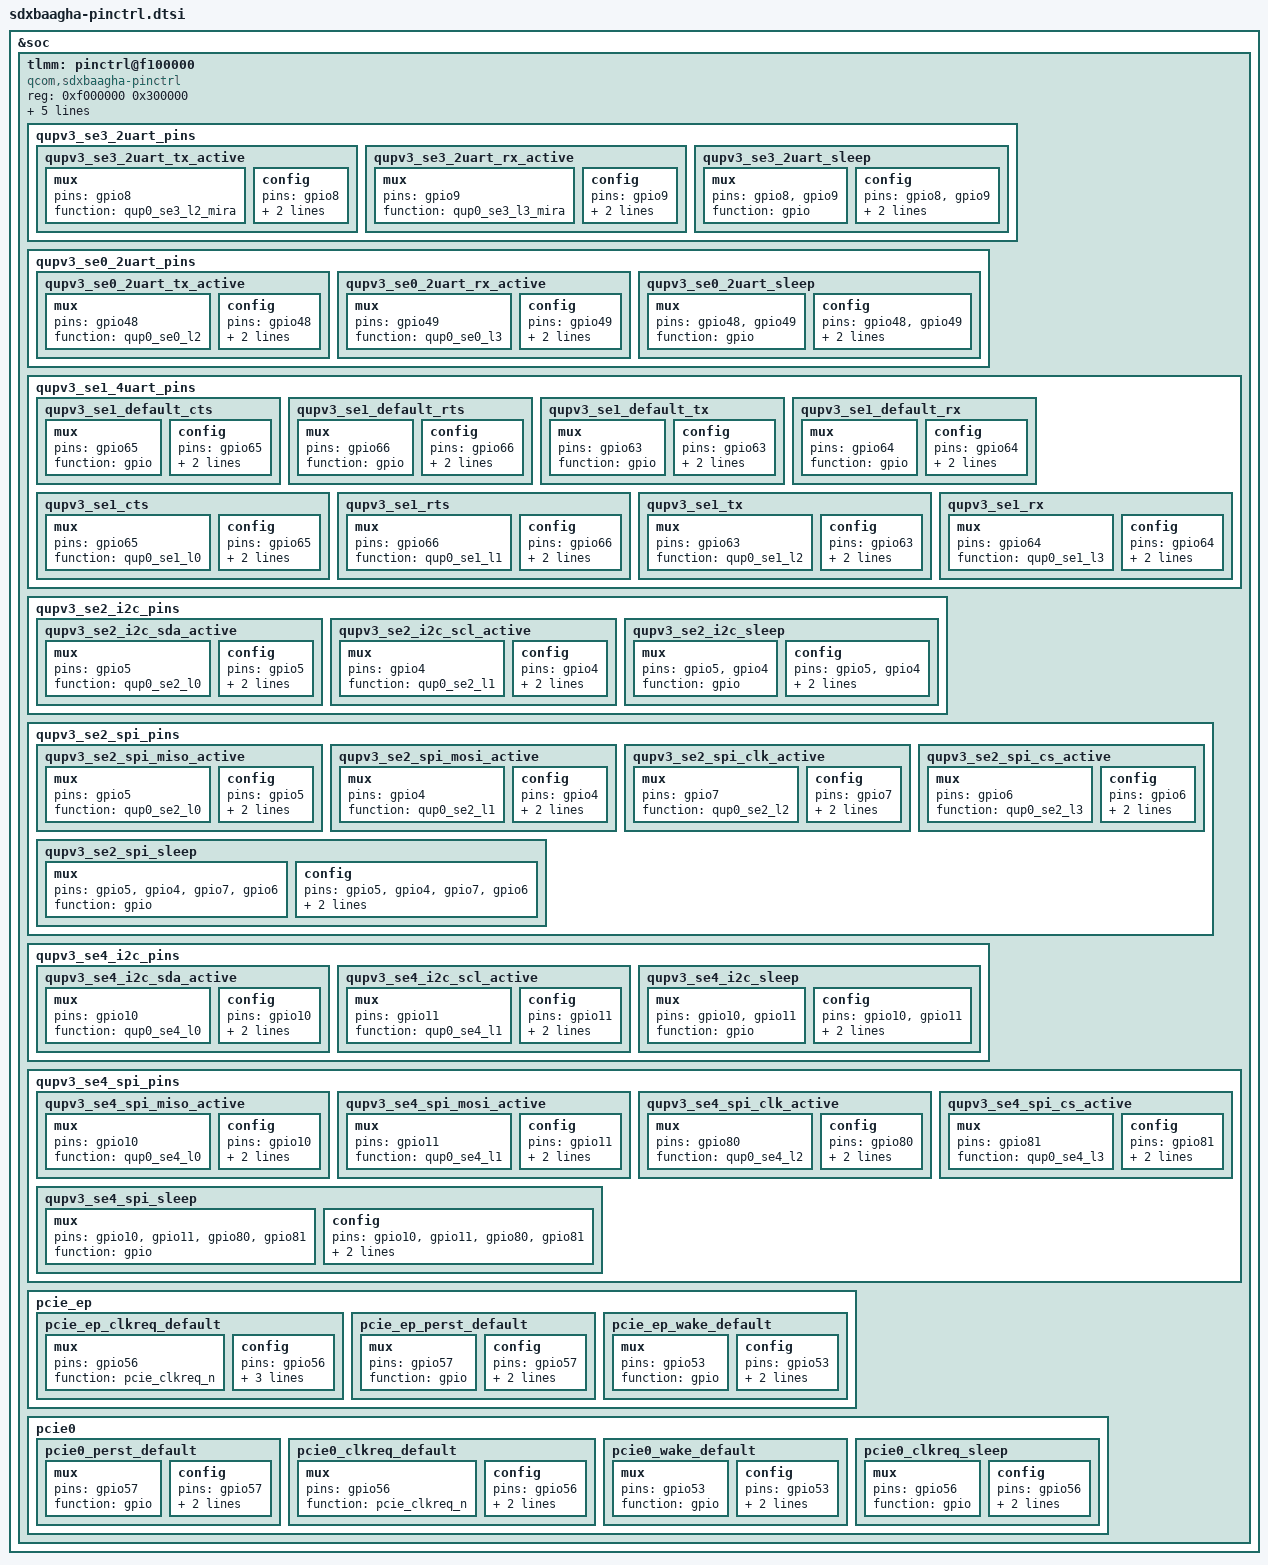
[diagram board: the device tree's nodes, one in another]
&soc {
	tlmm: pinctrl@f100000 {
		compatible = "qcom,sdxbaagha-pinctrl";
		reg = <0xf000000 0x300000>;
		interrupts = <GIC_SPI 139 IRQ_TYPE_LEVEL_HIGH>;
		gpio-controller;
		#gpio-cells = <2>;
		interrupt-controller;
		interrupt-parent = <&intc>;
		#interrupt-cells = <2>;
		wakeup-parent = <&pdc>;

		qupv3_se3_2uart_pins: qupv3_se3_2uart_pins {
			qupv3_se3_2uart_tx_active: qupv3_se3_2uart_tx_active {
				mux {
					pins = "gpio8";
					function = "qup0_se3_l2_mira";
				};

				config {
					pins = "gpio8";
					drive-strength = <2>;
					bias-disable;
				};
			};

			qupv3_se3_2uart_rx_active: qupv3_se3_2uart_rx_active {
				mux {
					pins = "gpio9";
					function = "qup0_se3_l3_mira";
				};

				config {
					pins = "gpio9";
					drive-strength = <2>;
					bias-disable;
				};
			};

			qupv3_se3_2uart_sleep: qupv3_se3_2uart_sleep {
				mux {
					pins = "gpio8", "gpio9";
					function = "gpio";
				};

				config {
					pins = "gpio8", "gpio9";
					drive-strength = <2>;
					bias-pull-down;
				};
			};
		};

		qupv3_se0_2uart_pins: qupv3_se0_2uart_pins {
			qupv3_se0_2uart_tx_active: qupv3_se0_2uart_tx_active {
				mux {
					pins = "gpio48";
					function = "qup0_se0_l2";
				};

				config {
					pins = "gpio48";
					drive-strength = <2>;
					bias-disable;
				};
			};

			qupv3_se0_2uart_rx_active: qupv3_se0_2uart_rx_active {
				mux {
					pins = "gpio49";
					function = "qup0_se0_l3";
				};

				config {
					pins = "gpio49";
					drive-strength = <2>;
					bias-disable;
				};
			};

			qupv3_se0_2uart_sleep: qupv3_se0_2uart_sleep {
				mux {
					pins = "gpio48", "gpio49";
					function = "gpio";
				};

				config {
					pins = "gpio48", "gpio49";
					drive-strength = <2>;
					bias-pull-down;
				};
			};
		};

		qupv3_se1_4uart_pins: qupv3_se1_4uart_pins {
			qupv3_se1_default_cts: qupv3_se1_default_cts {
				mux {
					pins = "gpio65";
					function = "gpio";
				};

				config {
					pins = "gpio65";
					drive-strength = <2>;
					bias-disable;
				};
			};

			qupv3_se1_default_rts: qupv3_se1_default_rts {
				mux {
					pins = "gpio66";
					function = "gpio";
				};

				config {
					pins = "gpio66";
					drive-strength = <2>;
					bias-pull-down;
				};
			};

			qupv3_se1_default_tx: qupv3_se1_default_tx {
				mux {
					pins = "gpio63";
					function = "gpio";
				};

				config {
					pins = "gpio63";
					drive-strength = <2>;
					bias-pull-up;
				};
			};

			qupv3_se1_default_rx: qupv3_se1_default_rx {
				mux {
					pins = "gpio64";
					function = "gpio";
				};

				config {
					pins = "gpio64";
					drive-strength = <2>;
					bias-pull-down;
				};
			};

			qupv3_se1_cts: qupv3_se1_cts {
				mux {
					pins = "gpio65";
					function = "qup0_se1_l0";
				};

				config {
					pins = "gpio65";
					drive-strength = <2>;
					bias-disable;
				};
			};

			qupv3_se1_rts: qupv3_se1_rts {
				mux {
					pins = "gpio66";
					function = "qup0_se1_l1";
				};

				config {
					pins = "gpio66";
					drive-strength = <2>;
					bias-pull-down;
				};
			};

			qupv3_se1_tx: qupv3_se1_tx {
				mux {
					pins = "gpio63";
					function = "qup0_se1_l2";
				};

				config {
					pins = "gpio63";
					drive-strength = <2>;
					bias-pull-up;
				};
			};

			qupv3_se1_rx: qupv3_se1_rx {
				mux {
					pins = "gpio64";
					function = "qup0_se1_l3";
				};

				config {
					pins = "gpio64";
					drive-strength = <2>;
					bias-disable;
				};
			};
		};

		qupv3_se2_i2c_pins: qupv3_se2_i2c_pins {
			qupv3_se2_i2c_sda_active: qupv3_se2_i2c_sda_active {
				mux {
					pins = "gpio5";
					function = "qup0_se2_l0";
				};

				config {
					pins = "gpio5";
					drive-strength = <2>;
					bias-pull-up;
				};
			};

			qupv3_se2_i2c_scl_active: qupv3_se2_i2c_scl_active {
				mux {
					pins = "gpio4";
					function = "qup0_se2_l1";
				};

				config {
					pins = "gpio4";
					drive-strength = <2>;
					bias-pull-up;
				};
			};

			qupv3_se2_i2c_sleep: qupv3_se2_i2c_sleep {
				mux {
					pins = "gpio5", "gpio4";
					function = "gpio";
				};

				config {
					pins = "gpio5", "gpio4";
					drive-strength = <2>;
					bias-pull-down;
				};
			};
		};

		qupv3_se2_spi_pins: qupv3_se2_spi_pins {
			qupv3_se2_spi_miso_active: qupv3_se2_spi_miso_active {
				mux {
					pins = "gpio5";
					function = "qup0_se2_l0";
				};

				config {
					pins = "gpio5";
					drive-strength = <6>;
					bias-disable;
				};
			};

			qupv3_se2_spi_mosi_active: qupv3_se2_spi_mosi_active {
				mux {
					pins = "gpio4";
					function = "qup0_se2_l1";
				};

				config {
					pins = "gpio4";
					drive-strength = <6>;
					bias-disable;
				};
			};

			qupv3_se2_spi_clk_active: qupv3_se2_spi_clk_active {
				mux {
					pins = "gpio7";
					function = "qup0_se2_l2";
				};

				config {
					pins = "gpio7";
					drive-strength = <6>;
					bias-disable;
				};
			};

			qupv3_se2_spi_cs_active: qupv3_se2_spi_cs_active {
				mux {
					pins = "gpio6";
					function = "qup0_se2_l3";
				};

				config {
					pins = "gpio6";
					drive-strength = <6>;
					bias-disable;
				};
			};

			qupv3_se2_spi_sleep: qupv3_se2_spi_sleep {
				mux {
					pins = "gpio5", "gpio4",
						"gpio7", "gpio6";
					function = "gpio";
				};

				config {
					pins = "gpio5", "gpio4",
						"gpio7", "gpio6";
					drive-strength = <2>;
					bias-pull-down;
				};
			};
		};

		qupv3_se4_i2c_pins: qupv3_se4_i2c_pins {
			qupv3_se4_i2c_sda_active: qupv3_se4_i2c_sda_active {
				mux {
					pins = "gpio10";
					function = "qup0_se4_l0";
				};

				config {
					pins = "gpio10";
					drive-strength = <2>;
					bias-pull-up;
				};
			};

			qupv3_se4_i2c_scl_active: qupv3_se4_i2c_scl_active {
				mux {
					pins = "gpio11";
					function = "qup0_se4_l1";
				};

				config {
					pins = "gpio11";
					drive-strength = <2>;
					bias-pull-up;
				};
			};

			qupv3_se4_i2c_sleep: qupv3_se4_i2c_sleep {
				mux {
					pins = "gpio10", "gpio11";
					function = "gpio";
				};

				config {
					pins = "gpio10", "gpio11";
					drive-strength = <2>;
					bias-pull-down;
				};
			};
		};

		qupv3_se4_spi_pins: qupv3_se4_spi_pins {
			qupv3_se4_spi_miso_active: qupv3_se4_spi_miso_active {
				mux {
					pins = "gpio10";
					function = "qup0_se4_l0";
				};

				config {
					pins = "gpio10";
					drive-strength = <6>;
					bias-disable;
				};
			};

			qupv3_se4_spi_mosi_active: qupv3_se4_spi_mosi_active {
				mux {
					pins = "gpio11";
					function = "qup0_se4_l1";
				};

				config {
					pins = "gpio11";
					drive-strength = <6>;
					bias-disable;
				};
			};

			qupv3_se4_spi_clk_active: qupv3_se4_spi_clk_active {
				mux {
					pins = "gpio80";
					function = "qup0_se4_l2";
				};

				config {
					pins = "gpio80";
					drive-strength = <6>;
					bias-disable;
				};
			};

			qupv3_se4_spi_cs_active: qupv3_se4_spi_cs_active {
				mux {
					pins = "gpio81";
					function = "qup0_se4_l3";
				};

				config {
					pins = "gpio81";
					drive-strength = <6>;
					bias-disable;
				};
			};

			qupv3_se4_spi_sleep: qupv3_se4_spi_sleep {
				mux {
					pins = "gpio10", "gpio11",
						"gpio80", "gpio81";
					function = "gpio";
				};

				config {
					pins = "gpio10", "gpio11",
						"gpio80", "gpio81";
					drive-strength = <2>;
					bias-pull-down;
				};
			};
		};


		pcie_ep {
			pcie_ep_clkreq_default: pcie_ep_clkreq_default {
				mux {
					pins = "gpio56";
					function = "pcie_clkreq_n";
				};

				config {
					pins = "gpio56";
					drive-strength = <2>;
					bias-pull-down;
					input-enable;
				};
			};

			pcie_ep_perst_default: pcie_ep_perst_default {
				mux {
					pins = "gpio57";
					function = "gpio";
				};

				config {
					pins = "gpio57";
					drive-strength = <2>;
					bias-pull-down;
				};
			};

			pcie_ep_wake_default: pcie_ep_wake_default {
				mux {
					pins = "gpio53";
					function = "gpio";
				};

				config {
					pins = "gpio53";
					drive-strength = <2>;
					bias-disable;
				};
			};
		};

		pcie0 {
			pcie0_perst_default: pcie0_perst_default {
				mux {
					pins = "gpio57";
					function = "gpio";
				};

				config {
					pins = "gpio57";
					drive-strength = <2>;
					bias-pull-down;
				};
			};

			pcie0_clkreq_default: pcie0_clkreq_default {
				mux {
					pins = "gpio56";
					function = "pcie_clkreq_n";
				};

				config {
					pins = "gpio56";
					drive-strength = <2>;
					bias-pull-up;
				};
			};

			pcie0_wake_default: pcie0_wake_default {
				mux {
					pins = "gpio53";
					function = "gpio";
				};

				config {
					pins = "gpio53";
					drive-strength = <2>;
					bias-pull-up;
				};
			};

			pcie0_clkreq_sleep: pcie0_clkreq_sleep {
				mux {
					pins = "gpio56";
					function = "gpio";
				};

				config {
					pins = "gpio56";
					drive-strength = <2>;
					bias-pull-up;
				};
			};
		};
	};
};
